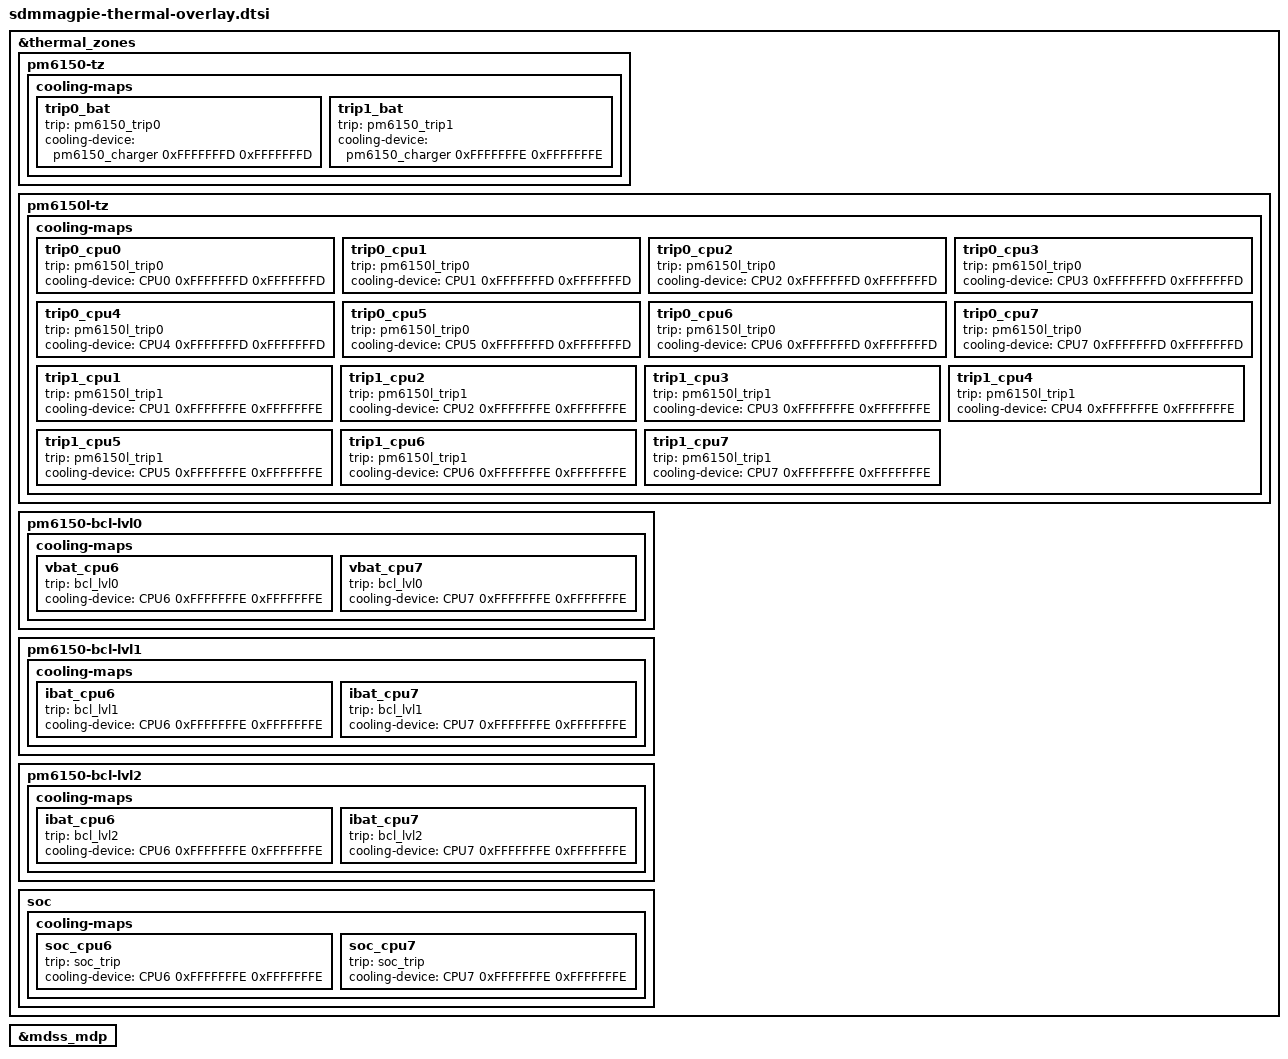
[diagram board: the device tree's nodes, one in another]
/*
 * Copyright (c) 2018-2019, The Linux Foundation. All rights reserved.
 *
 * This program is free software; you can redistribute it and/or modify
 * it under the terms of the GNU General Public License version 2 and
 * only version 2 as published by the Free Software Foundation.
 *
 * This program is distributed in the hope that it will be useful,
 * but WITHOUT ANY WARRANTY; without even the implied warranty of
 * MERCHANTABILITY or FITNESS FOR A PARTICULAR PURPOSE.  See the
 * GNU General Public License for more details.
 */
/* THERMAL_NO_LIMIT=0xFFFFFFFF, THERMAL_MAX_LIMIT=0xFFFFFFFE (hardcoded for DTC overlay compat) */

&thermal_zones {
	pm6150-tz {
		cooling-maps {
			trip0_bat {
				trip = <&pm6150_trip0>;
				cooling-device =
					<&pm6150_charger 0xFFFFFFFD
						0xFFFFFFFD>;
			};
			trip1_bat {
				trip = <&pm6150_trip1>;
				cooling-device =
					<&pm6150_charger 0xFFFFFFFE
						0xFFFFFFFE>;
			};
		};
	};

	pm6150l-tz {
		cooling-maps {
			trip0_cpu0 {
				trip = <&pm6150l_trip0>;
				cooling-device =
					<&CPU0 0xFFFFFFFD
						0xFFFFFFFD>;
			};
			trip0_cpu1 {
				trip = <&pm6150l_trip0>;
				cooling-device =
					<&CPU1 0xFFFFFFFD
						0xFFFFFFFD>;
			};
			trip0_cpu2 {
				trip = <&pm6150l_trip0>;
				cooling-device =
					<&CPU2 0xFFFFFFFD
						0xFFFFFFFD>;
			};
			trip0_cpu3 {
				trip = <&pm6150l_trip0>;
				cooling-device =
					<&CPU3 0xFFFFFFFD
						0xFFFFFFFD>;
			};
			trip0_cpu4 {
				trip = <&pm6150l_trip0>;
				cooling-device =
					<&CPU4 0xFFFFFFFD
						0xFFFFFFFD>;
			};
			trip0_cpu5 {
				trip = <&pm6150l_trip0>;
				cooling-device =
					<&CPU5 0xFFFFFFFD
						0xFFFFFFFD>;
			};
			trip0_cpu6 {
				trip = <&pm6150l_trip0>;
				cooling-device =
					<&CPU6 0xFFFFFFFD
						0xFFFFFFFD>;
			};
			trip0_cpu7 {
				trip = <&pm6150l_trip0>;
				cooling-device =
					<&CPU7 0xFFFFFFFD
						0xFFFFFFFD>;
			};
			trip1_cpu1 {
				trip = <&pm6150l_trip1>;
				cooling-device =
					<&CPU1 0xFFFFFFFE
						0xFFFFFFFE>;
			};
			trip1_cpu2 {
				trip = <&pm6150l_trip1>;
				cooling-device =
					<&CPU2 0xFFFFFFFE
						0xFFFFFFFE>;
			};
			trip1_cpu3 {
				trip = <&pm6150l_trip1>;
				cooling-device =
					<&CPU3 0xFFFFFFFE
						0xFFFFFFFE>;
			};
			trip1_cpu4 {
				trip = <&pm6150l_trip1>;
				cooling-device =
					<&CPU4 0xFFFFFFFE
						0xFFFFFFFE>;
			};
			trip1_cpu5 {
				trip = <&pm6150l_trip1>;
				cooling-device =
					<&CPU5 0xFFFFFFFE
						0xFFFFFFFE>;
			};
			trip1_cpu6 {
				trip = <&pm6150l_trip1>;
				cooling-device =
					<&CPU6 0xFFFFFFFE
						0xFFFFFFFE>;
			};
			trip1_cpu7 {
				trip = <&pm6150l_trip1>;
				cooling-device =
					<&CPU7 0xFFFFFFFE
						0xFFFFFFFE>;
			};
		};
	};

	pm6150-bcl-lvl0 {
		cooling-maps {
			vbat_cpu6 {
				trip = <&bcl_lvl0>;
				cooling-device =
					<&CPU6 0xFFFFFFFE
						0xFFFFFFFE>;
			};
			vbat_cpu7 {
				trip = <&bcl_lvl0>;
				cooling-device =
					<&CPU7 0xFFFFFFFE
						0xFFFFFFFE>;
			};
		};
	};

	pm6150-bcl-lvl1 {
		cooling-maps {
			ibat_cpu6 {
				trip = <&bcl_lvl1>;
				cooling-device =
					<&CPU6 0xFFFFFFFE
						0xFFFFFFFE>;
			};
			ibat_cpu7 {
				trip = <&bcl_lvl1>;
				cooling-device =
					<&CPU7 0xFFFFFFFE
						0xFFFFFFFE>;
			};
		};
	};

	pm6150-bcl-lvl2 {
		cooling-maps {
			ibat_cpu6 {
				trip = <&bcl_lvl2>;
				cooling-device =
					<&CPU6 0xFFFFFFFE
						0xFFFFFFFE>;
			};
			ibat_cpu7 {
				trip = <&bcl_lvl2>;
				cooling-device =
					<&CPU7 0xFFFFFFFE
						0xFFFFFFFE>;
			};
		};
	};

	soc {
		cooling-maps {
			soc_cpu6 {
				trip = <&soc_trip>;
				cooling-device =
					<&CPU6 0xFFFFFFFE
						0xFFFFFFFE>;
			};
			soc_cpu7 {
				trip = <&soc_trip>;
				cooling-device =
					<&CPU7 0xFFFFFFFE
						0xFFFFFFFE>;
			};
		};
	};
};

&mdss_mdp {
	#cooling-cells = <2>;
};
